# PIC32MX575F512L register map
Vendor: Microchip
Registers are 32-bit, read-write, reset 0x0 unless marked. A register's access mark holds for its fields unless they carry their own. Addresses are absolute, and some are shared; only a register's first bit layout is shown; [hi:lo] are bit positions.

## OCMP3
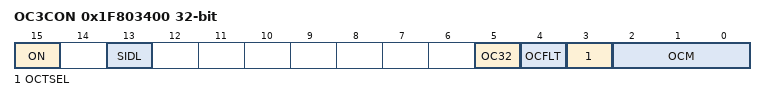
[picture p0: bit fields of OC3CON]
0x1F803400 OC3CON
  [15] ON, [13] SIDL, [5] OC32, [4] OCFLT ro, [3] OCTSEL, [2:0] OCM
0x1F803410 OC3R reset not defined — (power-on value xxxxxxxxxxxxxxxxxxxxxxxxxxxxxxxx)
0x1F803420 OC3RS reset not defined — (power-on value xxxxxxxxxxxxxxxxxxxxxxxxxxxxxxxx)

## OCMP4
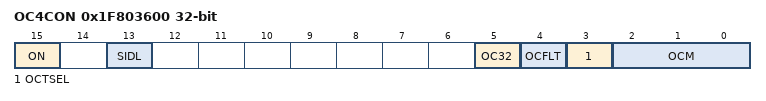
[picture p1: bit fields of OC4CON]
0x1F803600 OC4CON
  [15] ON, [13] SIDL, [5] OC32, [4] OCFLT ro, [3] OCTSEL, [2:0] OCM
0x1F803610 OC4R reset not defined — (power-on value xxxxxxxxxxxxxxxxxxxxxxxxxxxxxxxx)
0x1F803620 OC4RS reset not defined — (power-on value xxxxxxxxxxxxxxxxxxxxxxxxxxxxxxxx)

## OCMP5
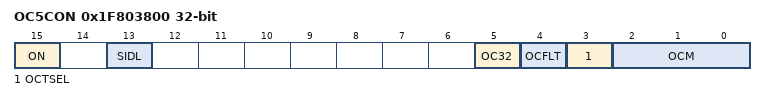
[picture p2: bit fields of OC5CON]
0x1F803800 OC5CON
  [15] ON, [13] SIDL, [5] OC32, [4] OCFLT ro, [3] OCTSEL, [2:0] OCM
0x1F803810 OC5R reset not defined — (power-on value xxxxxxxxxxxxxxxxxxxxxxxxxxxxxxxx)
0x1F803820 OC5RS reset not defined — (power-on value xxxxxxxxxxxxxxxxxxxxxxxxxxxxxxxx)

## I2C3
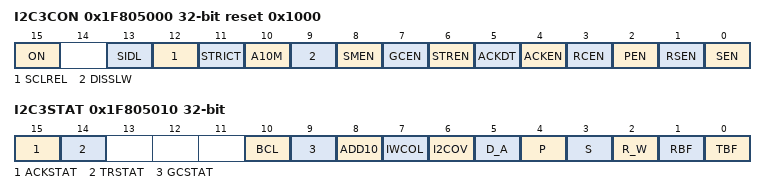
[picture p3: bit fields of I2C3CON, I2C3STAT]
0x1F805000 I2C3CON reset 0x1000
  [15] ON, [13] SIDL, [12] SCLREL, [11] STRICT, [10] A10M, [9] DISSLW, [8] SMEN, [7] GCEN, [6] STREN, [5] ACKDT, [4] ACKEN, [3] RCEN, [2] PEN, [1] RSEN, [0] SEN
0x1F805010 I2C3STAT
  [15] ACKSTAT ro
  [14] TRSTAT ro
  [10] BCL — (can only be cleared)
  [9] GCSTAT ro
  [8] ADD10 ro
  [7] IWCOL — (can only be cleared)
  [6] I2COV — (can only be cleared)
  [5] D_A ro
  [4] P — (can only be cleared)
  [3] S — (can only be cleared)
  [2] R_W ro
  [1] RBF ro
  [0] TBF ro
0x1F805020 I2C3ADD
  [9:0] I2CADD
0x1F805030 I2C3MSK
  [9:0] I2CMSK
0x1F805040 I2C3BRG
  [11:0] I2CBRG
0x1F805050 I2C3TRN
  [7:0] I2CTRN
0x1F805060 I2C3RCV
  [7:0] I2CRCV

## I2C4
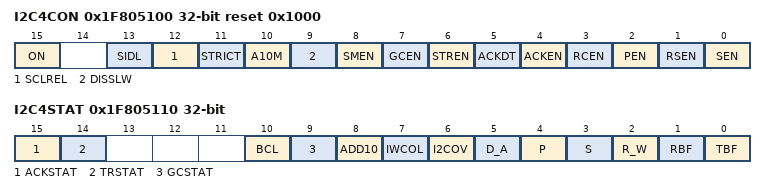
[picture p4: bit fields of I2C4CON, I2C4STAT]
0x1F805100 I2C4CON reset 0x1000
  [15] ON, [13] SIDL, [12] SCLREL, [11] STRICT, [10] A10M, [9] DISSLW, [8] SMEN, [7] GCEN, [6] STREN, [5] ACKDT, [4] ACKEN, [3] RCEN, [2] PEN, [1] RSEN, [0] SEN
0x1F805110 I2C4STAT
  [15] ACKSTAT ro
  [14] TRSTAT ro
  [10] BCL — (can only be cleared)
  [9] GCSTAT ro
  [8] ADD10 ro
  [7] IWCOL — (can only be cleared)
  [6] I2COV — (can only be cleared)
  [5] D_A ro
  [4] P — (can only be cleared)
  [3] S — (can only be cleared)
  [2] R_W ro
  [1] RBF ro
  [0] TBF ro
0x1F805120 I2C4ADD
  [9:0] I2CADD
0x1F805130 I2C4MSK
  [9:0] I2CMSK
0x1F805140 I2C4BRG
  [11:0] I2CBRG
0x1F805150 I2C4TRN
  [7:0] I2CTRN
0x1F805160 I2C4RCV
  [7:0] I2CRCV

## I2C5
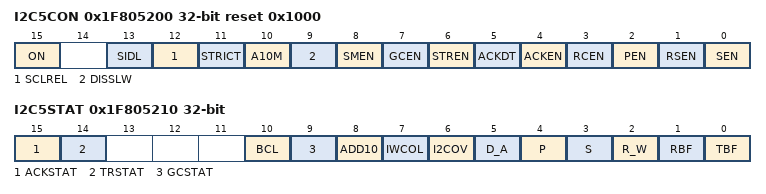
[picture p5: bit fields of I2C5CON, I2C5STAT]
0x1F805200 I2C5CON reset 0x1000
  [15] ON, [13] SIDL, [12] SCLREL, [11] STRICT, [10] A10M, [9] DISSLW, [8] SMEN, [7] GCEN, [6] STREN, [5] ACKDT, [4] ACKEN, [3] RCEN, [2] PEN, [1] RSEN, [0] SEN
0x1F805210 I2C5STAT
  [15] ACKSTAT ro
  [14] TRSTAT ro
  [10] BCL — (can only be cleared)
  [9] GCSTAT ro
  [8] ADD10 ro
  [7] IWCOL — (can only be cleared)
  [6] I2COV — (can only be cleared)
  [5] D_A ro
  [4] P — (can only be cleared)
  [3] S — (can only be cleared)
  [2] R_W ro
  [1] RBF ro
  [0] TBF ro
0x1F805220 I2C5ADD
  [9:0] I2CADD
0x1F805230 I2C5MSK
  [9:0] I2CMSK
0x1F805240 I2C5BRG
  [11:0] I2CBRG
0x1F805250 I2C5TRN
  [7:0] I2CTRN
0x1F805260 I2C5RCV
  [7:0] I2CRCV

## I2C1
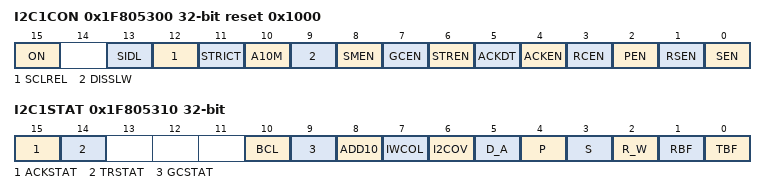
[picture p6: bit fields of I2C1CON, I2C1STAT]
0x1F805300 I2C1CON reset 0x1000
  [15] ON, [13] SIDL, [12] SCLREL, [11] STRICT, [10] A10M, [9] DISSLW, [8] SMEN, [7] GCEN, [6] STREN, [5] ACKDT, [4] ACKEN, [3] RCEN, [2] PEN, [1] RSEN, [0] SEN
0x1F805310 I2C1STAT
  [15] ACKSTAT ro
  [14] TRSTAT ro
  [10] BCL — (can only be cleared)
  [9] GCSTAT ro
  [8] ADD10 ro
  [7] IWCOL — (can only be cleared)
  [6] I2COV — (can only be cleared)
  [5] D_A ro
  [4] P — (can only be cleared)
  [3] S — (can only be cleared)
  [2] R_W ro
  [1] RBF ro
  [0] TBF ro
0x1F805320 I2C1ADD
  [9:0] I2CADD
0x1F805330 I2C1MSK
  [9:0] I2CMSK
0x1F805340 I2C1BRG
  [11:0] I2CBRG
0x1F805350 I2C1TRN
  [7:0] I2CTRN
0x1F805360 I2C1RCV
  [7:0] I2CRCV
